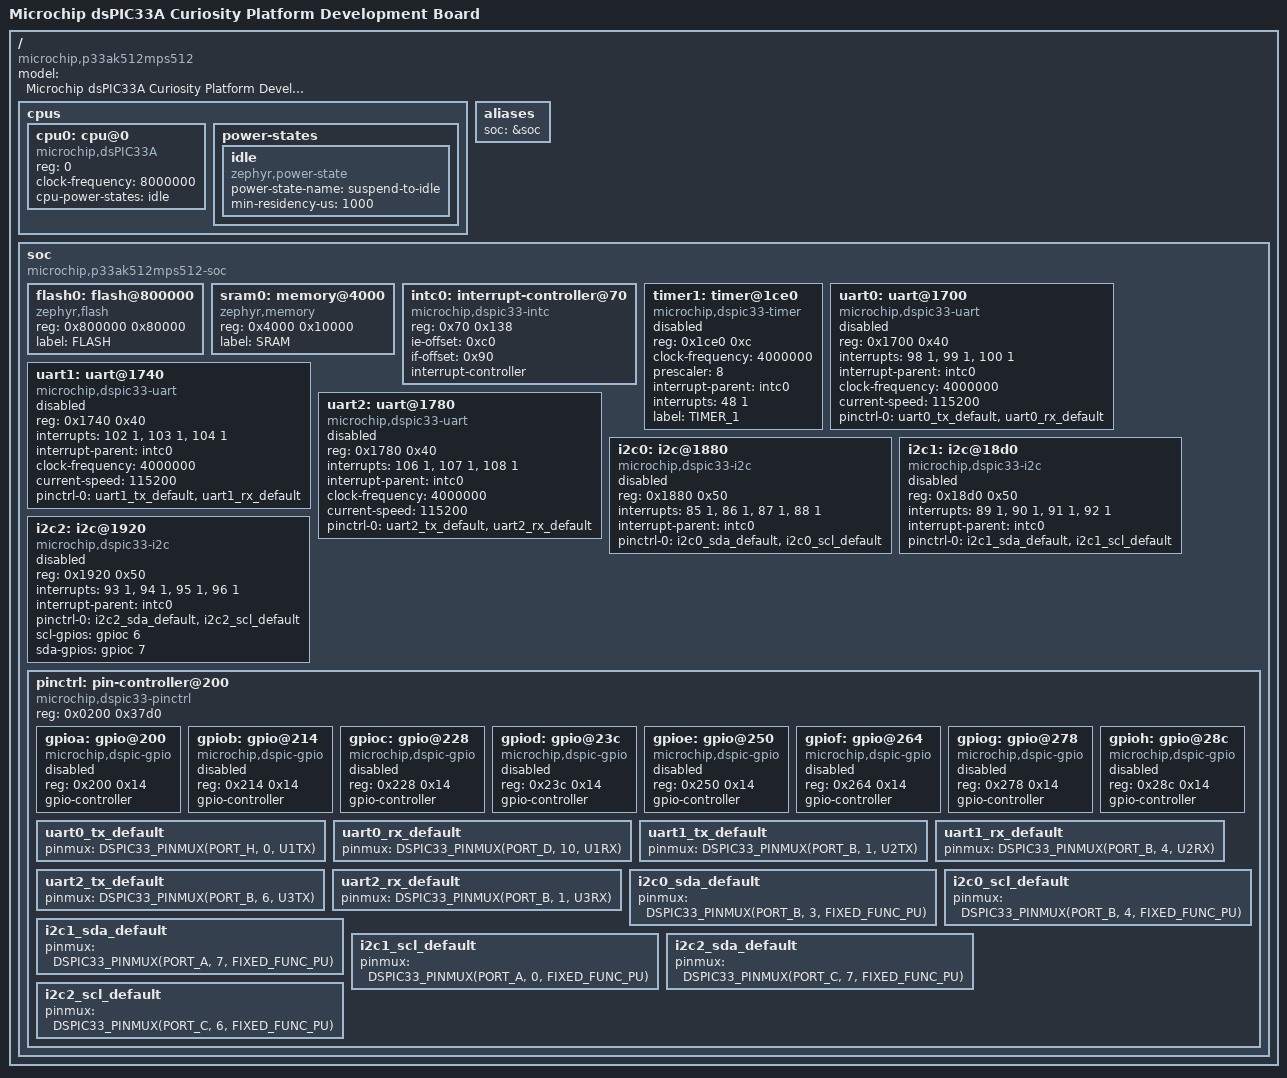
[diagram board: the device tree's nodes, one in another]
/*
 * Copyright (c) 2025, Microchip Technology Inc.
 * SPDX-License-Identifier: Apache-2.0
 */

#include "zephyr/dt-bindings/pinctrl/mchp-p33ak512mps512-pinctrl.h"

/ {
	model = "Microchip dsPIC33A Curiosity Platform Development Board";
	compatible = "microchip,p33ak512mps512";

	cpus {
		#address-cells = <1>;
		#size-cells = <0>;

		cpu0: cpu@0 {
			device_type = "cpu";
			compatible = "microchip,dsPIC33A";
			reg = <0>;
			clock-frequency = <8000000>;
			status = "okay";
			cpu-power-states = <&idle>;
		};

		power-states {
			idle: idle {
				compatible = "zephyr,power-state";
				power-state-name = "suspend-to-idle";
				min-residency-us = <1000>;
			};
		};
	};

	aliases {
		soc = &soc;
	};

	soc: soc {
		compatible = "microchip,p33ak512mps512-soc";
		#address-cells = <1>;
		#size-cells = <1>;

		flash0: flash@800000 {
			compatible = "zephyr,flash";
			reg = <0x800000 0x80000>;
			label = "FLASH";
		};

		sram0: memory@4000 {
			compatible = "zephyr,memory";
			reg = <0x4000 0x10000>;
			label = "SRAM";
		};

		intc0: interrupt-controller@70 {
			compatible = "microchip,dspic33-intc";
			reg = <0x70 0x138>;
			ie-offset = <0xc0>;
			if-offset = <0x90>;
			interrupt-controller;
			#address-cells = <0>;
			#interrupt-cells = <2>;
		};

		timer1: timer@1ce0 {
			compatible = "microchip,dspic33-timer";
			reg = <0x1ce0 0xc>;
			clock-frequency = <4000000>;
			prescaler = <8>;
			interrupt-parent = <&intc0>;
			interrupts = <48 1>;
			label = "TIMER_1";
			status = "disabled";
		};

		uart0: uart@1700 {
			compatible = "microchip,dspic33-uart";
			reg = <0x1700 0x40>;
			interrupts = <98 1>, <99 1>, <100 1>;
			interrupt-names = "rx", "tx", "err";
			interrupt-parent = <&intc0>;
			clock-frequency = <4000000>;
			current-speed = <115200>;
			pinctrl-0 = <&uart0_tx_default &uart0_rx_default>;
			pinctrl-names = "default";
			status = "disabled";
		};

		uart1: uart@1740 {
			compatible = "microchip,dspic33-uart";
			reg = <0x1740 0x40>;
			interrupts = <102 1>, <103 1>, <104 1>;
			interrupt-names = "rx", "tx", "err";
			interrupt-parent = <&intc0>;
			clock-frequency = <4000000>;
			current-speed = <115200>;
			pinctrl-0 = <&uart1_tx_default &uart1_rx_default>;
			pinctrl-names = "default";
			status = "disabled";
		};

		uart2: uart@1780 {
			compatible = "microchip,dspic33-uart";
			reg = <0x1780 0x40>;
			interrupts = <106 1>, <107 1>, <108 1>;
			interrupt-names = "rx", "tx", "err";
			interrupt-parent = <&intc0>;
			clock-frequency = <4000000>;
			current-speed = <115200>;
			pinctrl-0 = <&uart2_tx_default &uart2_rx_default>;
			pinctrl-names = "default";
			status = "disabled";
		};

		i2c0: i2c@1880 {
			compatible = "microchip,dspic33-i2c";
			reg = <0x1880 0x50>;
			interrupts = <85 1>, <86 1>, <87 1>, <88 1>;
			interrupt-names = "err", "gen", "rx", "tx";
			interrupt-parent = <&intc0>;
			pinctrl-0 = <&i2c0_sda_default &i2c0_scl_default>;
			pinctrl-names = "default";
			#address-cells = <1>;
			#size-cells = <0>;
			status = "disabled";
		};

		i2c1: i2c@18d0 {
			compatible = "microchip,dspic33-i2c";
			reg = <0x18d0 0x50>;
			interrupts = <89 1>, <90 1>, <91 1>, <92 1>;
			interrupt-names = "err", "gen", "rx", "tx";
			interrupt-parent = <&intc0>;
			pinctrl-0 = <&i2c1_sda_default &i2c1_scl_default>;
			pinctrl-names = "default";
			#address-cells = <1>;
			#size-cells = <0>;
			status = "disabled";
		};

		i2c2: i2c@1920 {
			compatible = "microchip,dspic33-i2c";
			reg = <0x1920 0x50>;
			interrupts = <93 1>, <94 1>, <95 1>, <96 1>;
			interrupt-names = "err", "gen", "rx", "tx";
			interrupt-parent = <&intc0>;
			pinctrl-0 = <&i2c2_sda_default &i2c2_scl_default>;
			pinctrl-names = "default";
			scl-gpios = <&gpioc 6 0>;
			sda-gpios = <&gpioc 7 0>;
			#address-cells = <1>;
			#size-cells = <0>;
			status = "disabled";
		};

		pinctrl: pin-controller@200 {
			compatible = "microchip,dspic33-pinctrl";
			reg = <0x0200 0x37d0>;
			#address-cells = <1>;
			#size-cells = <1>;
			status = "okay";

			gpioa: gpio@200 {
				compatible = "microchip,dspic-gpio";
				reg = <0x200 0x14>;
				gpio-controller;
				#gpio-cells = <2>;
				status = "disabled";
			};

			gpiob: gpio@214 {
				compatible = "microchip,dspic-gpio";
				reg = <0x214 0x14>;
				gpio-controller;
				#gpio-cells = <2>;
				status = "disabled";
			};

			gpioc: gpio@228 {
				compatible = "microchip,dspic-gpio";
				reg = <0x228 0x14>;
				gpio-controller;
				#gpio-cells = <2>;
				status = "disabled";
			};

			gpiod: gpio@23c {
				compatible = "microchip,dspic-gpio";
				reg = <0x23c 0x14>;
				gpio-controller;
				#gpio-cells = <2>;
				status = "disabled";
			};

			gpioe: gpio@250 {
				compatible = "microchip,dspic-gpio";
				reg = <0x250 0x14>;
				gpio-controller;
				#gpio-cells = <2>;
				status = "disabled";
			};

			gpiof: gpio@264 {
				compatible = "microchip,dspic-gpio";
				reg = <0x264 0x14>;
				gpio-controller;
				#gpio-cells = <2>;
				status = "disabled";
			};

			gpiog: gpio@278 {
				compatible = "microchip,dspic-gpio";
				reg = <0x278 0x14>;
				gpio-controller;
				#gpio-cells = <2>;
				status = "disabled";
			};

			gpioh: gpio@28c {
				compatible = "microchip,dspic-gpio";
				reg = <0x28c 0x14>;
				gpio-controller;
				#gpio-cells = <2>;
				status = "disabled";
			};

			uart0_tx_default: uart0_tx_default {
				pinmux = <DSPIC33_PINMUX(PORT_H, 0, U1TX)>;
			};

			uart0_rx_default: uart0_rx_default {
				pinmux = <DSPIC33_PINMUX(PORT_D, 10, U1RX)>;
			};

			uart1_tx_default: uart1_tx_default {
				pinmux = <DSPIC33_PINMUX(PORT_B, 1, U2TX)>;
			};

			uart1_rx_default: uart1_rx_default {
				pinmux = <DSPIC33_PINMUX(PORT_B, 4, U2RX)>;
			};

			uart2_tx_default: uart2_tx_default {
				pinmux = <DSPIC33_PINMUX(PORT_B, 6, U3TX)>;
			};

			uart2_rx_default: uart2_rx_default {
				pinmux = <DSPIC33_PINMUX(PORT_B, 1, U3RX)>;
			};

			i2c0_sda_default: i2c0_sda_default {
				pinmux = <DSPIC33_PINMUX(PORT_B, 3, FIXED_FUNC_PU)>;
			};

			i2c0_scl_default: i2c0_scl_default {
				pinmux = <DSPIC33_PINMUX(PORT_B, 4, FIXED_FUNC_PU)>;
			};

			i2c1_sda_default: i2c1_sda_default {
				pinmux = <DSPIC33_PINMUX(PORT_A, 7, FIXED_FUNC_PU)>;
			};

			i2c1_scl_default: i2c1_scl_default {
				pinmux = <DSPIC33_PINMUX(PORT_A, 0, FIXED_FUNC_PU)>;
			};

			i2c2_sda_default: i2c2_sda_default {
				pinmux = <DSPIC33_PINMUX(PORT_C, 7, FIXED_FUNC_PU)>;
			};

			i2c2_scl_default: i2c2_scl_default {
				pinmux = <DSPIC33_PINMUX(PORT_C, 6, FIXED_FUNC_PU)>;
			};
		};
	};
};
